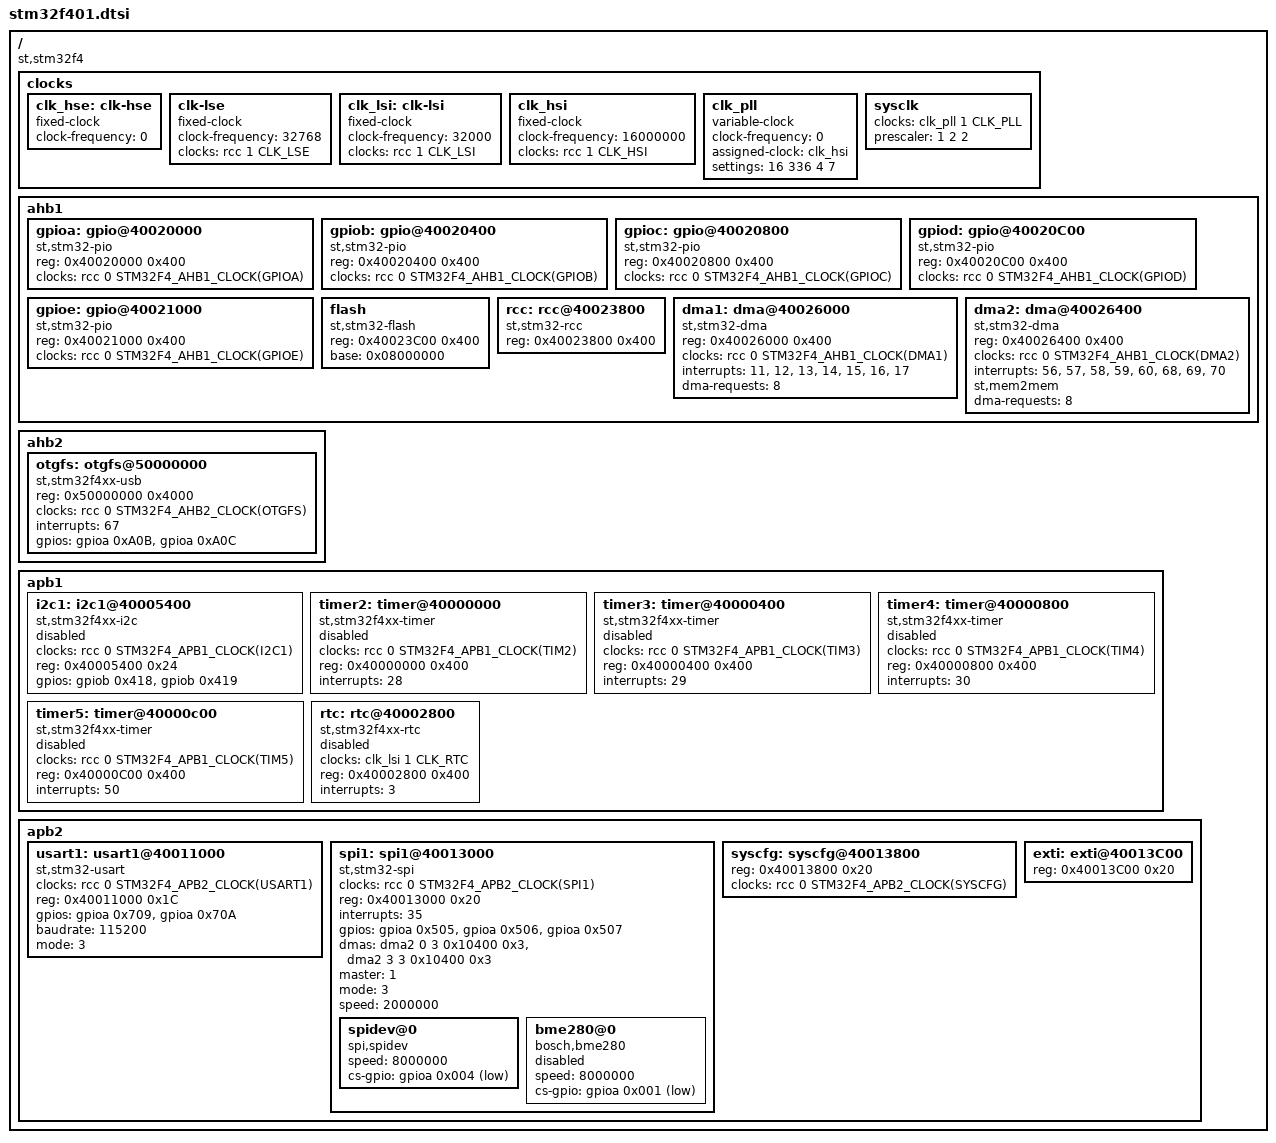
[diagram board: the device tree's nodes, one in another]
#include <dt-bindings/stm32fx-clock.h>
#include <dt-bindings/stm32f4-rcc.h>

/ {
    compatible = "st,stm32f4";

    #address-cells = <1>;
    #size-cells = <1>;

	clocks {

		clk_hse: clk-hse {
			#clock-cells = <0>;
			compatible = "fixed-clock";
			clock-frequency = <0>;
		};

		clk-lse {
			#clock-cells = <0>;
			compatible = "fixed-clock";
			clock-frequency = <32768>;
			clocks = <&rcc 1 CLK_LSE>;
		};

		clk_lsi: clk-lsi {
			#clock-cells = <0>;
			compatible = "fixed-clock";
			clock-frequency = <32000>;
			clocks = <&rcc 1 CLK_LSI>;
		};

		clk_hsi: clk_hsi {
			#clock-cells = <0>;
			compatible = "fixed-clock";
			clock-frequency = <16000000>;
			clocks = <&rcc 1 CLK_HSI>;
		};

		clk_pll: clk_pll {
			#clock-cells = <0>;
			compatible = "variable-clock";
			clock-frequency = <0>;

			assigned-clock = <&clk_hsi>;

			settings = <16 336 4 7>;
		};

		sysclk {
			clocks = <&clk_pll 1 CLK_PLL>;
			prescaler = <1 2 2>;		// ahb div1, apb1&apb2 div=2
		};
	};

	ahb1 {
		#address-cells = <1>;
		#size-cells = <1>;

		gpioa: gpio@40020000 {
			reg = <0x40020000 0x400>;
			clocks = <&rcc 0 STM32F4_AHB1_CLOCK(GPIOA)>;
			compatible = "st,stm32-pio";
                        status = "okay";
		};

		gpiob: gpio@40020400 {
			reg = <0x40020400 0x400>;
			clocks = <&rcc 0 STM32F4_AHB1_CLOCK(GPIOB)>;
			compatible = "st,stm32-pio";
                        status = "okay";
		};

		gpioc: gpio@40020800 {
			reg = <0x40020800 0x400>;
			clocks = <&rcc 0 STM32F4_AHB1_CLOCK(GPIOC)>;
			compatible = "st,stm32-pio";
                        status = "okay";
		};

		gpiod: gpio@40020C00 {
			reg = <0x40020C00 0x400>;
			clocks = <&rcc 0 STM32F4_AHB1_CLOCK(GPIOD)>;
			compatible = "st,stm32-pio";
                        status = "okay";
		};

		gpioe: gpio@40021000 {
			reg = <0x40021000 0x400>;
			clocks = <&rcc 0 STM32F4_AHB1_CLOCK(GPIOE)>;
			compatible = "st,stm32-pio";
                        status = "okay";
		};

		flash {
			#address-cells = <1>;
			#size-cells = <0>;
			compatible = "st,stm32-flash";
			reg = <0x40023C00 0x400>;
			base = <0x08000000>;
                        status = "okay";
		};

		rcc: rcc@40023800 {
			#clock-cells = <2>;
			reg = <0x40023800 0x400>;
			compatible = "st,stm32-rcc";
                        status = "okay";
		};

		dma1: dma@40026000 {
			reg = <0x40026000 0x400>;
			clocks = <&rcc 0 STM32F4_AHB1_CLOCK(DMA1)>;
			compatible = "st,stm32-dma";
			interrupts = <11>,
				     <12>,
				     <13>,
				     <14>,
				     <15>,
				     <16>,
				     <17>;
			dma-requests = <8>;
                        status = "okay";
		};

		dma2: dma@40026400 {
			reg = <0x40026400 0x400>;
			clocks = <&rcc 0 STM32F4_AHB1_CLOCK(DMA2)>;
			compatible = "st,stm32-dma";
			interrupts = <56>,
				     <57>,
				     <58>,
				     <59>,
				     <60>,
				     <68>,
				     <69>,
				     <70>;
			st,mem2mem;
			dma-requests = <8>;
                        status = "okay";
		};
	};

	ahb2 {
		#address-cells = <1>;
		#size-cells = <1>;

		otgfs: otgfs@50000000 {
			reg = <0x50000000 0x4000>;
			clocks = <&rcc 0 STM32F4_AHB2_CLOCK(OTGFS)>;
			compatible = "st,stm32f4xx-usb";
			interrupts = <67>;

			gpios = <&gpioa 0xA0B 0x18>,
				<&gpioa 0xA0C 0x18>;
			status = "okay";
		};
	};

	apb1 {
		#address-cells = <1>;
		#size-cells = <1>;

		i2c1: i2c1@40005400 {
			#address-cells = <1>;
			#size-cells = <0>;
			compatible = "st,stm32f4xx-i2c";
			clocks = <&rcc 0 STM32F4_APB1_CLOCK(I2C1)>;
			reg = <0x40005400 0x24>;
			gpios = <&gpiob 0x418 0x0E>,    /* SCL PB8 */
					<&gpiob 0x419 0x0E>;    /* SDA PB9 */
                        status = "disabled";
		};


                timer2: timer@40000000 {
                        compatible = "st,stm32f4xx-timer";
			clocks = <&rcc 0 STM32F4_APB1_CLOCK(TIM2)>;
                        reg = <0x40000000 0x400>;
                        interrupts = <28>;
                        status = "disabled";
                };

                timer3: timer@40000400 {
                        compatible = "st,stm32f4xx-timer";
			clocks = <&rcc 0 STM32F4_APB1_CLOCK(TIM3)>;
                        reg = <0x40000400 0x400>;
                        interrupts = <29>;
                        status = "disabled";
                };

                timer4: timer@40000800 {
                        compatible = "st,stm32f4xx-timer";
			clocks = <&rcc 0 STM32F4_APB1_CLOCK(TIM4)>;
                        reg = <0x40000800 0x400>;
                        interrupts = <30>;
                        status = "disabled";
                };

                timer5: timer@40000c00 {
                        compatible = "st,stm32f4xx-timer";
			clocks = <&rcc 0 STM32F4_APB1_CLOCK(TIM5)>;
                        reg = <0x40000C00 0x400>;
                        interrupts = <50>;
                        status = "disabled";
                };

		rtc: rtc@40002800 {
			compatible = "st,stm32f4xx-rtc";
			clocks = <&clk_lsi 1 CLK_RTC>;
			reg = <0x40002800 0x400>;
			interrupts = <3>;
			status = "disabled";

		};
	};

	apb2 {
		#address-cells = <1>;
		#size-cells = <1>;

		usart1: usart1@40011000 {
			compatible = "st,stm32-usart";
			clocks = <&rcc 0 STM32F4_APB2_CLOCK(USART1)>;
			reg = <0x40011000 0x1C>;
			gpios = <&gpioa 0x709 0>,     /* TX PA2 */
				<&gpioa 0x70A 0>;     /* RX PA3 */
			baudrate = <115200>;
			mode = <3>;
                        status = "okay";
		};

		spi1: spi1@40013000 {
			#address-cells = <1>;
			#size-cells = <0>;
			compatible = "st,stm32-spi";
			clocks = <&rcc 0 STM32F4_APB2_CLOCK(SPI1)>;
			reg = <0x40013000 0x20>;
                        interrupts = <35>;
			gpios =	<&gpioa 0x505 0x0A>,     /* SCK, PA5 */
					<&gpioa 0x506 0x08>,     /* MISO PA6 */
					<&gpioa 0x507 0x0A>;     /* MOSI PA7 */
			dmas = <&dma2 0 3 0x10400 0x3>,
				<&dma2 3 3 0x10400 0x3>;
			dma-names = "rx", "tx";

			master = <1>;
			mode = <3>;
			speed = <2000000>;

			status = "okay";

			spidev@0 {
				compatible = "spi,spidev";
				status = "okay";
				speed = <8000000>;
				cs-gpio = <&gpioa 0x004 0x3>;
			};

			bme280@0 {
				compatible = "bosch,bme280";
				status = "disabled";
				speed = <8000000>;
				cs-gpio = <&gpioa 0x001 0x3>;
			};
		};

		syscfg: syscfg@40013800 {
			reg = <0x40013800 0x20>;
			clocks = <&rcc 0 STM32F4_APB2_CLOCK(SYSCFG)>;
		};

		exti: exti@40013C00 {
			reg = <0x40013C00 0x20>;
		};
	};
};
